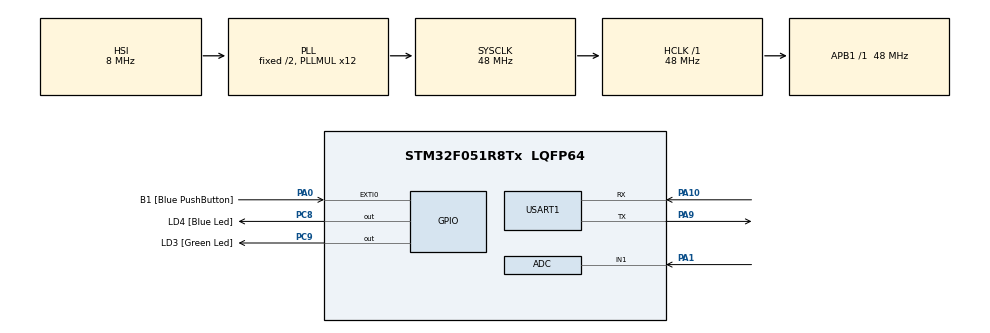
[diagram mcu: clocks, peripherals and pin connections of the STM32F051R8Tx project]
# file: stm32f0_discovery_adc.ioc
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Mcu.Family=STM32F0
Mcu.Name=STM32F051R8Tx
Mcu.Package=LQFP64
PA0.GPIO_Label=B1 [Blue PushButton]
PA0.GPIO_ModeDefaultEXTI=GPIO_MODE_EVT_RISING
PA0.Signal=GPXTI0
PA1.Mode=IN1
PA1.Signal=ADC_IN1
PA10.Mode=Asynchronous
PA10.Signal=USART1_RX
PA13.GPIO_Label=SWDIO
PA13.Mode=Serial_Wire
PA13.Signal=SYS_SWDIO
PA14.GPIO_Label=SWCLK
PA14.Mode=Serial_Wire
PA14.Signal=SYS_SWCLK
PA9.Mode=Asynchronous
PA9.Signal=USART1_TX
PC8.GPIO_Label=LD4 [Blue Led]
PC8.Signal=GPIO_Output
PC9.GPIO_Label=LD3 [Green Led]
PC9.Signal=GPIO_Output
ProjectManager.HeapSize=0x200
ProjectManager.StackSize=0x400
ProjectManager.TargetToolchain=SW4STM32
RCC.AHBFreq_Value=48000000
RCC.APB1Freq_Value=48000000
RCC.APB1TimFreq_Value=48000000
RCC.HCLKFreq_Value=48000000
RCC.PLLMUL=RCC_PLL_MUL12
RCC.SYSCLKFreq_VALUE=48000000
RCC.SYSCLKSource=RCC_SYSCLKSOURCE_PLLCLK
USART1.VirtualMode-Asynchronous=VM_ASYNC
board=STM32F0DISCOVERY

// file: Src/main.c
/* USER CODE BEGIN Header */
/**
  ******************************************************************************
  * @file           : main.c
  * @brief          : Main program body
  ******************************************************************************
  * @attention
  *
  * <h2><center>&copy; Copyright (c) 2019 STMicroelectronics.
  * All rights reserved.</center></h2>
  *
  * This software component is licensed by ST under BSD 3-Clause license,
  * the "License"; You may not use this file except in compliance with the
  * License. You may obtain a copy of the License at:
  *                        opensource.org/licenses/BSD-3-Clause
  *
  ******************************************************************************
  */
/* USER CODE END Header */

#include "main.h"
#include "stdlib.h"
#include "inttypes.h"
#include "string.h"

ADC_HandleTypeDef hadc;

UART_HandleTypeDef huart1;

void SystemClock_Config(void);
static void MX_GPIO_Init(void);
static void MX_ADC_Init(void);
static void MX_USART1_UART_Init(void);

int main(void)
{

  /* MCU Configuration--------------------------------------------------------*/

  /* Reset of all peripherals, Initializes the Flash interface and the Systick. */
  HAL_Init();

  /* Configure the system clock */
  SystemClock_Config();

  /* Initialize all configured peripherals */
  MX_GPIO_Init();
  MX_ADC_Init();
  MX_USART1_UART_Init();

  /* Infinite loop */
  /* USER CODE BEGIN WHILE */
  HAL_ADCEx_Calibration_Start(&hadc);
  while (1)
  {
    /* USER CODE END WHILE */
    // HAL_GPIO_TogglePin(LD3_GPIO_Port, LD3_Pin);
    // HAL_Delay(500);   // 500ms
    HAL_ADC_Start(&hadc);
    HAL_ADC_PollForConversion(&hadc, 1);
    uint32_t adc_raw = HAL_ADC_GetValue(&hadc);
    float adc_voltage = adc_raw * (3.0f / 0xFFF); // 3.0V / 12 bit
    float current = (adc_voltage - 1.5) * 0.110; // 110mV / A
    char buf[10];
    itoa(current * 1000, buf, 10);
    strcat(buf,"\n");
    HAL_UART_Transmit(&huart1, (uint8_t*) buf, strlen(buf), 10);

  }
}

void SystemClock_Config(void)
{
  RCC_OscInitTypeDef RCC_OscInitStruct = {0};
  RCC_ClkInitTypeDef RCC_ClkInitStruct = {0};
  RCC_PeriphCLKInitTypeDef PeriphClkInit = {0};

  /** Initializes the CPU, AHB and APB busses clocks
  */
  RCC_OscInitStruct.OscillatorType = RCC_OSCILLATORTYPE_HSI|RCC_OSCILLATORTYPE_HSI14;
  RCC_OscInitStruct.HSIState = RCC_HSI_ON;
  RCC_OscInitStruct.HSI14State = RCC_HSI14_ON;
  RCC_OscInitStruct.HSICalibrationValue = RCC_HSICALIBRATION_DEFAULT;
  RCC_OscInitStruct.HSI14CalibrationValue = 16;
  RCC_OscInitStruct.PLL.PLLState = RCC_PLL_ON;
  RCC_OscInitStruct.PLL.PLLSource = RCC_PLLSOURCE_HSI;
  RCC_OscInitStruct.PLL.PLLMUL = RCC_PLL_MUL12;
  RCC_OscInitStruct.PLL.PREDIV = RCC_PREDIV_DIV1;
  if (HAL_RCC_OscConfig(&RCC_OscInitStruct) != HAL_OK)
  {
    Error_Handler();
  }
  /** Initializes the CPU, AHB and APB busses clocks
  */
  RCC_ClkInitStruct.ClockType = RCC_CLOCKTYPE_HCLK|RCC_CLOCKTYPE_SYSCLK
                              |RCC_CLOCKTYPE_PCLK1;
  RCC_ClkInitStruct.SYSCLKSource = RCC_SYSCLKSOURCE_PLLCLK;
  RCC_ClkInitStruct.AHBCLKDivider = RCC_SYSCLK_DIV1;
  RCC_ClkInitStruct.APB1CLKDivider = RCC_HCLK_DIV1;

  if (HAL_RCC_ClockConfig(&RCC_ClkInitStruct, FLASH_LATENCY_1) != HAL_OK)
  {
    Error_Handler();
  }
  PeriphClkInit.PeriphClockSelection = RCC_PERIPHCLK_USART1;
  PeriphClkInit.Usart1ClockSelection = RCC_USART1CLKSOURCE_PCLK1;
  if (HAL_RCCEx_PeriphCLKConfig(&PeriphClkInit) != HAL_OK)
  {
    Error_Handler();
  }
}

static void MX_ADC_Init(void)
{

  ADC_ChannelConfTypeDef sConfig = {0};

  /** Configure the global features of the ADC (Clock, Resolution, Data Alignment and number of conversion)
  */
  hadc.Instance = ADC1;
  hadc.Init.ClockPrescaler = ADC_CLOCK_ASYNC_DIV1;
  hadc.Init.Resolution = ADC_RESOLUTION_12B;
  hadc.Init.DataAlign = ADC_DATAALIGN_RIGHT;
  hadc.Init.ScanConvMode = ADC_SCAN_DIRECTION_FORWARD;
  hadc.Init.EOCSelection = ADC_EOC_SINGLE_CONV;
  hadc.Init.LowPowerAutoWait = DISABLE;
  hadc.Init.LowPowerAutoPowerOff = DISABLE;
  hadc.Init.ContinuousConvMode = DISABLE;
  hadc.Init.DiscontinuousConvMode = DISABLE;
  hadc.Init.ExternalTrigConv = ADC_SOFTWARE_START;
  hadc.Init.ExternalTrigConvEdge = ADC_EXTERNALTRIGCONVEDGE_NONE;
  hadc.Init.DMAContinuousRequests = DISABLE;
  hadc.Init.Overrun = ADC_OVR_DATA_PRESERVED;
  if (HAL_ADC_Init(&hadc) != HAL_OK)
  {
    Error_Handler();
  }
  /** Configure for the selected ADC regular channel to be converted.
  */
  sConfig.Channel = ADC_CHANNEL_1;
  sConfig.Rank = ADC_RANK_CHANNEL_NUMBER;
  sConfig.SamplingTime = ADC_SAMPLETIME_1CYCLE_5;
  if (HAL_ADC_ConfigChannel(&hadc, &sConfig) != HAL_OK)
  {
    Error_Handler();
  }

}

static void MX_USART1_UART_Init(void)
{

  huart1.Instance = USART1;
  huart1.Init.BaudRate = 38400;
  huart1.Init.WordLength = UART_WORDLENGTH_8B;
  huart1.Init.StopBits = UART_STOPBITS_1;
  huart1.Init.Parity = UART_PARITY_NONE;
  huart1.Init.Mode = UART_MODE_TX_RX;
  huart1.Init.HwFlowCtl = UART_HWCONTROL_NONE;
  huart1.Init.OverSampling = UART_OVERSAMPLING_16;
  huart1.Init.OneBitSampling = UART_ONE_BIT_SAMPLE_DISABLE;
  huart1.AdvancedInit.AdvFeatureInit = UART_ADVFEATURE_NO_INIT;
  if (HAL_UART_Init(&huart1) != HAL_OK)
  {
    Error_Handler();
  }

}

static void MX_GPIO_Init(void)
{
  GPIO_InitTypeDef GPIO_InitStruct = {0};

  /* GPIO Ports Clock Enable */
  __HAL_RCC_GPIOA_CLK_ENABLE();
  __HAL_RCC_GPIOC_CLK_ENABLE();

  /*Configure GPIO pin Output Level */
  HAL_GPIO_WritePin(GPIOC, LD4_Pin|LD3_Pin, GPIO_PIN_RESET);

  /*Configure GPIO pin : B1_Pin */
  GPIO_InitStruct.Pin = B1_Pin;
  GPIO_InitStruct.Mode = GPIO_MODE_EVT_RISING;
  GPIO_InitStruct.Pull = GPIO_NOPULL;
  HAL_GPIO_Init(B1_GPIO_Port, &GPIO_InitStruct);

  /*Configure GPIO pins : LD4_Pin LD3_Pin */
  GPIO_InitStruct.Pin = LD4_Pin|LD3_Pin;
  GPIO_InitStruct.Mode = GPIO_MODE_OUTPUT_PP;
  GPIO_InitStruct.Pull = GPIO_NOPULL;
  GPIO_InitStruct.Speed = GPIO_SPEED_FREQ_LOW;
  HAL_GPIO_Init(GPIOC, &GPIO_InitStruct);

}

void Error_Handler(void)
{
}

/************************ (C) COPYRIGHT STMicroelectronics *****END OF FILE****/
